# f28004x_dcc_regs register map
Vendor: Texas Instruments
Peripheral module from a debugger description file (folder C2000).
Address unit: 16 bits
Registers are 32-bit, read-write, no defined reset value unless marked. A register's access mark holds for its fields unless they carry their own. Offsets are as the file gives them; lines under a group give offsets from that group; [hi:lo] are bit positions; {n}, {i} and the like mark numbered series; 'fields as' and 'values as' point back to an identical list; <NAME> marks a mode.

## DCC_REGS — DCC Registers
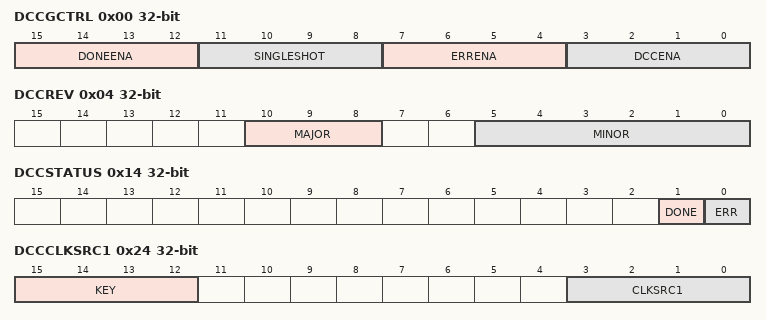
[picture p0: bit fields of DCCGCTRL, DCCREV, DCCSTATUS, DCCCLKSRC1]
0x00 DCCGCTRL — Global Control Register
  [15:12] DONEENA — DONE Enable
  [11:8] SINGLESHOT — Single-Shot Enable
  [7:4] ERRENA — Error Enable
  [3:0] DCCENA — DCC Enable
0x04 DCCREV ro — DCC Revision Register
  [10:8] MAJOR — Major Revision Number
  [5:0] MINOR — Minor Revision Number
0x08 DCCCNTSEED0 — Counter 0 Seed Value
  [19:0] COUNTSEED0 — Seed Value for Counter 0
0x0C DCCVALIDSEED0 — Valid 0 Seed Value
  [15:0] VALIDSEED — Seed Value for Valid Duration Counter 0
0x10 DCCCNTSEED1 — Counter 1 Seed Value
  [19:0] COUNTSEED1 — Seed Value for Counter 1
0x14 DCCSTATUS
  [1] DONE — Single-Shot Done Flag
  [0] ERR — Error Flag
0x18 DCCCNT0 ro — Counter 0 Value
  [19:0] COUNT0 — Current Value of Counter 0
0x1C DCCVALID0 ro — Valid Value 0
  [15:0] VALID0 — Current Value of Valid 0
0x20 DCCCNT1 ro — Counter 1 Value
  [19:0] COUNT1 — Current Value of Counter 1
0x24 DCCCLKSRC1 — Clock Source 1
  [15:12] KEY — Enables or Disables Clock Source Selection for COUNT1
  [3:0] CLKSRC1 — Clock Source Select for Counter 1
0x28 DCCCLKSRC0 — Clock Source 0
  [3:0] CLKSRC0 — Clock Source Select for Counter 0
